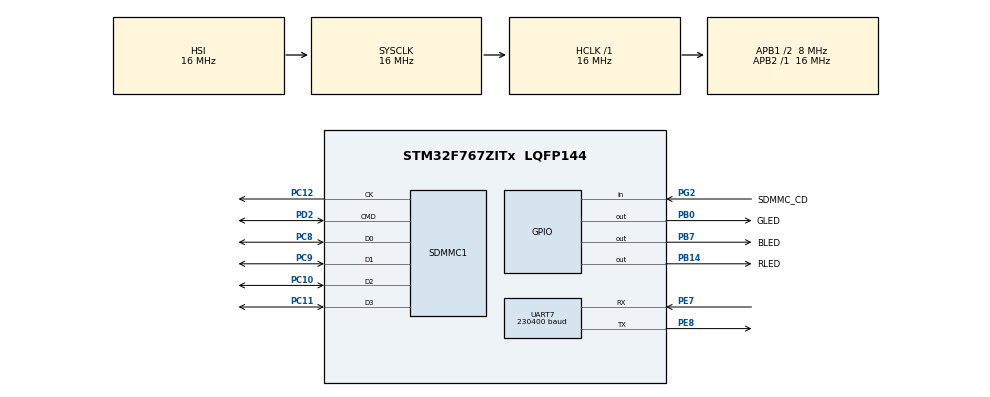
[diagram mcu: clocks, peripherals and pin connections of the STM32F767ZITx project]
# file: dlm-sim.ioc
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Mcu.Family=STM32F7
Dma.UART7_TX.2.Mode=DMA_NORMAL
RCC.CortexFreq_Value=16000000
PC10.GPIO_PuPd=GPIO_PULLUP
Dma.SDMMC1_RX.1.PeriphDataAlignment=DMA_PDATAALIGN_WORD
PG2.GPIO_PuPd=GPIO_PULLUP
Dma.SDMMC1_TX.0.Direction=DMA_MEMORY_TO_PERIPH
FATFS0.BSP.api=Unknown
VP_FATFS_VS_SDIO.Mode=SDIO
PG2.Signal=GPIO_Input
PC12.Signal=SDMMC1_CK
PC10.Signal=SDMMC1_D2
PB14.GPIO_Label=RLED
RCC.SYSCLKSourceVirtual=RCC_SYSCLKSOURCE_PLLCLK
PB0.GPIO_Label=GLED
Dma.SDMMC1_TX.0.Instance=DMA2_Stream3
Dma.SDMMC1_TX.0.Priority=DMA_PRIORITY_LOW
ProjectManager.StackSize=0x400
VP_FREERTOS_VS_CMSIS_V2.Mode=CMSIS_V2
NVIC.SDMMC1_IRQn=true\:5\:0\:false\:false\:true\:true\:true\:true
PC11.GPIO_PuPd=GPIO_PULLUP
Dma.SDMMC1_TX.0.FIFOMode=DMA_FIFOMODE_ENABLE
PC10.GPIO_Speed_High_Default=GPIO_SPEED_FREQ_VERY_HIGH
Dma.SDMMC1_RX.1.Mode=DMA_PFCTRL
Dma.UART7_TX.2.Priority=DMA_PRIORITY_LOW
RCC.HCLKFreq_Value=16000000
RCC.APB2TimFreq_Value=16000000
PC9.GPIO_Speed_High_Default=GPIO_SPEED_FREQ_VERY_HIGH
RCC.AHBFreq_Value=16000000
FATFS0.BSP.ip=GPIO
RCC.HSE_VALUE=16000000
FATFS0.BSP.i2caddr=0
RCC.PLLMUL=RCC_PLL_MUL9
Dma.UART7_TX.2.PeriphInc=DMA_PINC_DISABLE
PC9.Mode=SD_4_bits_Wide_bus
Dma.UART7_TX.2.MemDataAlignment=DMA_MDATAALIGN_BYTE
PB7.Signal=GPIO_Output
Dma.SDMMC1_TX.0.FIFOThreshold=DMA_FIFO_THRESHOLD_FULL
PB7.GPIO_Label=BLED
Dma.UART7_TX.2.FIFOMode=DMA_FIFOMODE_DISABLE
Mcu.Package=LQFP144
NVIC.TimeBase=TIM1_BRK_TIM9_IRQn
FATFS0.BSP.solution=PG2
NVIC.TimeBaseIP=TIM9
PC11.Mode=SD_4_bits_Wide_bus
Dma.UART7_TX.2.Instance=DMA1_Stream1
Dma.Request2=UART7_TX
Dma.Request1=SDMMC1_RX
RCC.APB1TimFreq_Value=16000000
PE7.Signal=UART7_RX
Dma.SDMMC1_RX.1.PeriphInc=DMA_PINC_DISABLE
Dma.Request0=SDMMC1_TX
PG2.GPIO_Label=SDMMC_CD
FATFS0.BSP.STBoard=false
FREERTOS.Tasks01=AcquireData,24,1024,Thread_AcquireData,Default,NULL,Dynamic,NULL,NULL;StoreData,32,1024,Thread_StoreData,Default,NULL,Dynamic,NULL,NULL;BroadcastData,32,1024,Thread_BroadcastData,Default,NULL,Dynamic,NULL,NULL
Dma.SDMMC1_RX.1.MemInc=DMA_MINC_ENABLE
PD2.GPIO_PuPd=GPIO_PULLUP
Dma.SDMMC1_RX.1.Instance=DMA2_Stream6
Dma.SDMMC1_TX.0.Mode=DMA_PFCTRL
PC11.Signal=SDMMC1_D3
FATFS0.BSP.mode=Input
Dma.SDMMC1_TX.0.MemDataAlignment=DMA_MDATAALIGN_WORD
PC8.Signal=SDMMC1_D0
PC10.Mode=SD_4_bits_Wide_bus
NVIC.DMA1_Stream1_IRQn=true\:5\:0\:false\:false\:true\:true\:false\:true
RCC.APB1CLKDivider=RCC_HCLK_DIV2
Dma.UART7_TX.2.PeriphDataAlignment=DMA_PDATAALIGN_BYTE
FATFS0.BSP.instance=PG2
PE8.Mode=Asynchronous
VP_SYS_VS_tim9.Mode=TIM9
Dma.SDMMC1_TX.0.PeriphBurst=DMA_PBURST_INC4
Dma.UART7_TX.2.MemInc=DMA_MINC_ENABLE
ProjectManager.TargetToolchain=STM32CubeIDE
Dma.SDMMC1_RX.1.MemDataAlignment=DMA_MDATAALIGN_WORD
PC11.GPIO_Speed_High_Default=GPIO_SPEED_FREQ_VERY_HIGH
RCC.USBFreq_Value=96000000
NVIC.DMA2_Stream3_IRQn=true\:5\:0\:false\:false\:true\:true\:false\:true
NVIC.DMA2_Stream6_IRQn=true\:5\:0\:false\:false\:true\:true\:false\:true
RCC.LSE_VALUE=32768
PB14.Signal=GPIO_Output
PD2.Mode=SD_4_bits_Wide_bus
FATFS.BSP.number=1
PC12.Mode=SD_4_bits_Wide_bus
board=NUCLEO-F767ZI
RCC.VCOOutputFreq_Value=192000000
RCC.APB2Freq_Value=16000000
RCC.PRESCALERUSB=RCC_USBCLKSOURCE_PLL_DIV1_5
PE8.Signal=UART7_TX
Dma.SDMMC1_TX.0.PeriphInc=DMA_PINC_DISABLE
Dma.SDMMC1_TX.0.MemBurst=DMA_MBURST_INC4
PC9.GPIO_PuPd=GPIO_PULLUP
Dma.SDMMC1_RX.1.FIFOMode=DMA_FIFOMODE_ENABLE
Mcu.Name=STM32F767ZITx
NVIC.TIM1_BRK_TIM9_IRQn=true\:0\:0\:false\:false\:true\:false\:false\:true
PC8.Mode=SD_4_bits_Wide_bus
PC12.GPIO_Speed_High_Default=GPIO_SPEED_FREQ_VERY_HIGH
RCC.48MHZClocksFreq_Value=24000000
PC8.GPIO_Speed_High_Default=GPIO_SPEED_FREQ_VERY_HIGH
PC8.GPIO_PuPd=GPIO_PULLUP
RCC.SYSCLKFreq_VALUE=16000000
PE7.Mode=Asynchronous
Dma.SDMMC1_RX.1.MemBurst=DMA_MBURST_INC4
Dma.SDMMC1_RX.1.PeriphBurst=DMA_PBURST_INC4
ProjectManager.HeapSize=0x200
UART7.BaudRate=230400
RCC.HSI_VALUE=16000000
Dma.SDMMC1_TX.0.MemInc=DMA_MINC_ENABLE
FREERTOS.Mutexes01=mutex_broadcast_buffer,Dynamic,NULL;mutex_storage_buffer,Dynamic,NULL
NVIC.PriorityGroup=NVIC_PRIORITYGROUP_4
Dma.SDMMC1_RX.1.Priority=DMA_PRIORITY_LOW
Dma.SDMMC1_RX.1.FIFOThreshold=DMA_FIFO_THRESHOLD_FULL
PC9.Signal=SDMMC1_D1
PD2.Signal=SDMMC1_CMD
PD2.GPIO_Speed_High_Default=GPIO_SPEED_FREQ_VERY_HIGH
Dma.SDMMC1_TX.0.PeriphDataAlignment=DMA_PDATAALIGN_WORD
RCC.APB1Freq_Value=8000000
PB0.Signal=GPIO_Output
Dma.UART7_TX.2.Direction=DMA_MEMORY_TO_PERIPH
FATFS0.BSP.name=Detect_SDIO
Dma.SDMMC1_RX.1.Direction=DMA_PERIPH_TO_MEMORY
NVIC.UART7_IRQn=true\:5\:0\:false\:false\:true\:true\:true\:true

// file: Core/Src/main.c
/* USER CODE BEGIN Header */
/**
  ******************************************************************************
  * @file           : main.c
  * @brief          : Main program body
  ******************************************************************************
  * @attention
  *
  * <h2><center>&copy; Copyright (c) 2022 STMicroelectronics.
  * All rights reserved.</center></h2>
  *
  * This software component is licensed by ST under BSD 3-Clause license,
  * the "License"; You may not use this file except in compliance with the
  * License. You may obtain a copy of the License at:
  *                        opensource.org/licenses/BSD-3-Clause
  *
  ******************************************************************************
  */
/* USER CODE END Header */
#include "main.h"
#include "cmsis_os.h"
#include "fatfs.h"

/* USER CODE BEGIN Includes */
#include "dlm.h"
/* USER CODE END Includes */

SD_HandleTypeDef hsd1;
DMA_HandleTypeDef hdma_sdmmc1_tx;
DMA_HandleTypeDef hdma_sdmmc1_rx;

UART_HandleTypeDef huart7;
DMA_HandleTypeDef hdma_uart7_tx;

/* Definitions for AcquireData */
osThreadId_t AcquireDataHandle;
const osThreadAttr_t AcquireData_attributes = {
  .name = "AcquireData",
  .stack_size = 1024 * 4,
  .priority = (osPriority_t) osPriorityNormal,
};
/* Definitions for StoreData */
osThreadId_t StoreDataHandle;
const osThreadAttr_t StoreData_attributes = {
  .name = "StoreData",
  .stack_size = 1024 * 4,
  .priority = (osPriority_t) osPriorityAboveNormal,
};
/* Definitions for BroadcastData */
osThreadId_t BroadcastDataHandle;
const osThreadAttr_t BroadcastData_attributes = {
  .name = "BroadcastData",
  .stack_size = 1024 * 4,
  .priority = (osPriority_t) osPriorityAboveNormal,
};
/* Definitions for mutex_broadcast_buffer */
osMutexId_t mutex_broadcast_bufferHandle;
const osMutexAttr_t mutex_broadcast_buffer_attributes = {
  .name = "mutex_broadcast_buffer"
};
/* Definitions for mutex_storage_buffer */
osMutexId_t mutex_storage_bufferHandle;
const osMutexAttr_t mutex_storage_buffer_attributes = {
  .name = "mutex_storage_buffer"
};

void SystemClock_Config(void);
static void MX_GPIO_Init(void);
static void MX_DMA_Init(void);
static void MX_SDMMC1_SD_Init(void);
static void MX_UART7_Init(void);
void Thread_AcquireData(void *argument);
void Thread_StoreData(void *argument);
void Thread_BroadcastData(void *argument);

int main(void)
{

  /* MCU Configuration--------------------------------------------------------*/

  /* Reset of all peripherals, Initializes the Flash interface and the Systick. */
  HAL_Init();

  /* USER CODE BEGIN Init */
  dlm_init();
  /* USER CODE END Init */

  /* Configure the system clock */
  SystemClock_Config();

  /* Initialize all configured peripherals */
  MX_GPIO_Init();
  MX_DMA_Init();
  MX_SDMMC1_SD_Init();
  MX_FATFS_Init();
  MX_UART7_Init();

  /* Init scheduler */
  osKernelInitialize();
  /* Create the mutex(es) */
  /* creation of mutex_broadcast_buffer */
  mutex_broadcast_bufferHandle = osMutexNew(&mutex_broadcast_buffer_attributes);

  /* creation of mutex_storage_buffer */
  mutex_storage_bufferHandle = osMutexNew(&mutex_storage_buffer_attributes);

  /* Create the thread(s) */
  /* creation of AcquireData */
  AcquireDataHandle = osThreadNew(Thread_AcquireData, NULL, &AcquireData_attributes);

  /* creation of StoreData */
  StoreDataHandle = osThreadNew(Thread_StoreData, NULL, &StoreData_attributes);

  /* creation of BroadcastData */
  BroadcastDataHandle = osThreadNew(Thread_BroadcastData, NULL, &BroadcastData_attributes);

  /* Start scheduler */
  osKernelStart();

  /* We should never get here as control is now taken by the scheduler */
  /* Infinite loop */
  while (1)
  {

  }
}

void SystemClock_Config(void)
{
  RCC_OscInitTypeDef RCC_OscInitStruct = {0};
  RCC_ClkInitTypeDef RCC_ClkInitStruct = {0};
  RCC_PeriphCLKInitTypeDef PeriphClkInitStruct = {0};

  /** Configure the main internal regulator output voltage
  */
  __HAL_RCC_PWR_CLK_ENABLE();
  __HAL_PWR_VOLTAGESCALING_CONFIG(PWR_REGULATOR_VOLTAGE_SCALE3);
  /** Initializes the RCC Oscillators according to the specified parameters
  * in the RCC_OscInitTypeDef structure.
  */
  RCC_OscInitStruct.OscillatorType = RCC_OSCILLATORTYPE_HSI;
  RCC_OscInitStruct.HSIState = RCC_HSI_ON;
  RCC_OscInitStruct.HSICalibrationValue = RCC_HSICALIBRATION_DEFAULT;
  RCC_OscInitStruct.PLL.PLLState = RCC_PLL_NONE;
  if (HAL_RCC_OscConfig(&RCC_OscInitStruct) != HAL_OK)
  {
    Error_Handler();
  }
  /** Initializes the CPU, AHB and APB buses clocks
  */
  RCC_ClkInitStruct.ClockType = RCC_CLOCKTYPE_HCLK|RCC_CLOCKTYPE_SYSCLK
                              |RCC_CLOCKTYPE_PCLK1|RCC_CLOCKTYPE_PCLK2;
  RCC_ClkInitStruct.SYSCLKSource = RCC_SYSCLKSOURCE_HSI;
  RCC_ClkInitStruct.AHBCLKDivider = RCC_SYSCLK_DIV1;
  RCC_ClkInitStruct.APB1CLKDivider = RCC_HCLK_DIV2;
  RCC_ClkInitStruct.APB2CLKDivider = RCC_HCLK_DIV1;

  if (HAL_RCC_ClockConfig(&RCC_ClkInitStruct, FLASH_LATENCY_0) != HAL_OK)
  {
    Error_Handler();
  }
  PeriphClkInitStruct.PeriphClockSelection = RCC_PERIPHCLK_UART7|RCC_PERIPHCLK_SDMMC1;
  PeriphClkInitStruct.Uart7ClockSelection = RCC_UART7CLKSOURCE_PCLK1;
  PeriphClkInitStruct.Sdmmc1ClockSelection = RCC_SDMMC1CLKSOURCE_SYSCLK;
  if (HAL_RCCEx_PeriphCLKConfig(&PeriphClkInitStruct) != HAL_OK)
  {
    Error_Handler();
  }
}

static void MX_SDMMC1_SD_Init(void)
{

  hsd1.Instance = SDMMC1;
  hsd1.Init.ClockEdge = SDMMC_CLOCK_EDGE_RISING;
  hsd1.Init.ClockBypass = SDMMC_CLOCK_BYPASS_DISABLE;
  hsd1.Init.ClockPowerSave = SDMMC_CLOCK_POWER_SAVE_DISABLE;
  hsd1.Init.BusWide = SDMMC_BUS_WIDE_1B;
  hsd1.Init.HardwareFlowControl = SDMMC_HARDWARE_FLOW_CONTROL_DISABLE;
  hsd1.Init.ClockDiv = 0;

}

static void MX_UART7_Init(void)
{

  huart7.Instance = UART7;
  huart7.Init.BaudRate = 230400;
  huart7.Init.WordLength = UART_WORDLENGTH_8B;
  huart7.Init.StopBits = UART_STOPBITS_1;
  huart7.Init.Parity = UART_PARITY_NONE;
  huart7.Init.Mode = UART_MODE_TX_RX;
  huart7.Init.HwFlowCtl = UART_HWCONTROL_NONE;
  huart7.Init.OverSampling = UART_OVERSAMPLING_16;
  huart7.Init.OneBitSampling = UART_ONE_BIT_SAMPLE_DISABLE;
  huart7.AdvancedInit.AdvFeatureInit = UART_ADVFEATURE_NO_INIT;
  if (HAL_UART_Init(&huart7) != HAL_OK)
  {
    Error_Handler();
  }

}

static void MX_DMA_Init(void)
{

  /* DMA controller clock enable */
  __HAL_RCC_DMA2_CLK_ENABLE();
  __HAL_RCC_DMA1_CLK_ENABLE();

  /* DMA interrupt init */
  /* DMA1_Stream1_IRQn interrupt configuration */
  HAL_NVIC_SetPriority(DMA1_Stream1_IRQn, 5, 0);
  HAL_NVIC_EnableIRQ(DMA1_Stream1_IRQn);
  /* DMA2_Stream3_IRQn interrupt configuration */
  HAL_NVIC_SetPriority(DMA2_Stream3_IRQn, 5, 0);
  HAL_NVIC_EnableIRQ(DMA2_Stream3_IRQn);
  /* DMA2_Stream6_IRQn interrupt configuration */
  HAL_NVIC_SetPriority(DMA2_Stream6_IRQn, 5, 0);
  HAL_NVIC_EnableIRQ(DMA2_Stream6_IRQn);

}

static void MX_GPIO_Init(void)
{
  GPIO_InitTypeDef GPIO_InitStruct = {0};

  /* GPIO Ports Clock Enable */
  __HAL_RCC_GPIOB_CLK_ENABLE();
  __HAL_RCC_GPIOE_CLK_ENABLE();
  __HAL_RCC_GPIOG_CLK_ENABLE();
  __HAL_RCC_GPIOC_CLK_ENABLE();
  __HAL_RCC_GPIOD_CLK_ENABLE();

  /*Configure GPIO pin Output Level */
  HAL_GPIO_WritePin(GPIOB, GLED_Pin|RLED_Pin|BLED_Pin, GPIO_PIN_RESET);

  /*Configure GPIO pins : GLED_Pin RLED_Pin BLED_Pin */
  GPIO_InitStruct.Pin = GLED_Pin|RLED_Pin|BLED_Pin;
  GPIO_InitStruct.Mode = GPIO_MODE_OUTPUT_PP;
  GPIO_InitStruct.Pull = GPIO_NOPULL;
  GPIO_InitStruct.Speed = GPIO_SPEED_FREQ_LOW;
  HAL_GPIO_Init(GPIOB, &GPIO_InitStruct);

  /*Configure GPIO pin : SDMMC_CD_Pin */
  GPIO_InitStruct.Pin = SDMMC_CD_Pin;
  GPIO_InitStruct.Mode = GPIO_MODE_INPUT;
  GPIO_InitStruct.Pull = GPIO_PULLUP;
  HAL_GPIO_Init(SDMMC_CD_GPIO_Port, &GPIO_InitStruct);

}

void Thread_AcquireData(void *argument)
{
  /* USER CODE BEGIN 5 */
  /* Infinite loop */
  for(;;)
  {
	  dlm_manage_data_acquisition();
  }
  /* USER CODE END 5 */
}

void Thread_StoreData(void *argument)
{
  /* USER CODE BEGIN Thread_StoreData */
  /* Infinite loop */
  for(;;)
  {
	  dlm_manage_data_storage();
  }
  /* USER CODE END Thread_StoreData */
}

void Thread_BroadcastData(void *argument)
{
  /* USER CODE BEGIN Thread_BroadcastData */
  /* Infinite loop */
  for(;;)
  {
	  dlm_manage_data_broadcast();
  }
  /* USER CODE END Thread_BroadcastData */
}

 /**
  * @brief  Period elapsed callback in non blocking mode
  * @note   This function is called  when TIM9 interrupt took place, inside
  * HAL_TIM_IRQHandler(). It makes a direct call to HAL_IncTick() to increment
  * a global variable "uwTick" used as application time base.
  * @param  htim : TIM handle
  * @retval None
  */
void HAL_TIM_PeriodElapsedCallback(TIM_HandleTypeDef *htim)
{
  if (htim->Instance == TIM9) {
    HAL_IncTick();
  }
}

void Error_Handler(void)
{
  __disable_irq();
  while (1)
  {
  }
}

/************************ (C) COPYRIGHT STMicroelectronics *****END OF FILE****/
